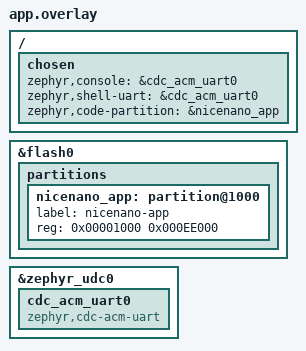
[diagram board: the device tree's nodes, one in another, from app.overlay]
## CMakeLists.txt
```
cmake_minimum_required(VERSION 3.20.0)
find_package(Zephyr REQUIRED HINTS $ENV{ZEPHYR_BASE})
project(nrf52840_nicenano_wire_check)
target_sources(app PRIVATE src/main.c ../nrf52840_nicenano_common/ael_usb.c)
```

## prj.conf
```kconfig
CONFIG_GPIO=y
CONFIG_SERIAL=y
CONFIG_CONSOLE=y
CONFIG_UART_CONSOLE=y
CONFIG_STDOUT_CONSOLE=y
CONFIG_PRINTK=y
CONFIG_USB_DEVICE_STACK_NEXT=y
CONFIG_USBD_CDC_ACM_CLASS=y
CONFIG_UART_LINE_CTRL=y
CONFIG_HWINFO=y
CONFIG_BUILD_OUTPUT_UF2=y
CONFIG_BUILD_OUTPUT_UF2_FAMILY_ID="0x239A00B3"
CONFIG_FLASH_LOAD_OFFSET=0x1000
CONFIG_FLASH_LOAD_SIZE=0xEE000
```

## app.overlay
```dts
/ {
    chosen {
        zephyr,console = &cdc_acm_uart0;
        zephyr,shell-uart = &cdc_acm_uart0;
        zephyr,code-partition = &nicenano_app;
    };
};

&flash0 {
    partitions {
        nicenano_app: partition@1000 {
            label = "nicenano-app";
            reg = <0x00001000 0x000EE000>;
        };
    };
};

&zephyr_udc0 {
    cdc_acm_uart0: cdc_acm_uart0 {
        compatible = "zephyr,cdc-acm-uart";
    };
};
```

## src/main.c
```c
/*
 * AEL Pre-Stage-2 — nRF52840 nice!nano wire connectivity check
 *
 * Drives each output pin LOW then HIGH and reads the paired input pin.
 * Reports CONNECTED if input follows output, OPEN otherwise.
 *
 * Connections tested:
 *   P0.17 (OUT) ↔ P0.20 (IN)   — GPIO/UART loopback wire
 *   P0.22 (OUT) → P0.24 (IN)   — PWM capture wire
 *   P1.10 (OUT) → P1.13 (IN)   — SPI MOSI→MISO wire
 *
 * Reports:
 *   [WIRE] P0.17->P0.20 CONNECTED|OPEN
 *   [WIRE] P0.22->P0.24 CONNECTED|OPEN
 *   [WIRE] P1.10->P1.13 CONNECTED|OPEN
 *   AEL_WIRE_CHECK_PASS|FAIL
 */

#include <zephyr/kernel.h>
#include <zephyr/sys/printk.h>
#include <zephyr/drivers/gpio.h>
#include "../../nrf52840_nicenano_common/ael_usb.h"

static const struct device *gpio0;
static const struct device *gpio1;

static bool check_wire(const char *tag,
                        const struct device *out_dev, int out_pin,
                        const struct device *in_dev,  int in_pin)
{
    gpio_pin_configure(out_dev, out_pin, GPIO_OUTPUT_INACTIVE);
    gpio_pin_configure(in_dev,  in_pin,  GPIO_INPUT);

    /* Drive LOW, read */
    gpio_pin_set(out_dev, out_pin, 0);
    k_busy_wait(50);
    int r0 = gpio_pin_get(in_dev, in_pin);

    /* Drive HIGH, read */
    gpio_pin_set(out_dev, out_pin, 1);
    k_busy_wait(50);
    int r1 = gpio_pin_get(in_dev, in_pin);

    /* Tristate output, check if input floats (connected → stays at last driven value) */
    gpio_pin_configure(out_dev, out_pin, GPIO_INPUT);

    bool connected = (r0 == 0 && r1 == 1);
    printk("[WIRE] %s %s\n", tag, connected ? "CONNECTED" : "OPEN");
    return connected;
}

int main(void)
{
    ael_usb_init();
    k_msleep(1500);

    gpio0 = DEVICE_DT_GET(DT_NODELABEL(gpio0));
    gpio1 = DEVICE_DT_GET(DT_NODELABEL(gpio1));

    if (!device_is_ready(gpio0) || !device_is_ready(gpio1)) {
        printk("[WIRE] gpio_not_ready FAIL\n");
        printk("AEL_WIRE_CHECK_FAIL\n");
        while (1) {
            if (atomic_get(&ael_bl_flag)) { k_msleep(50); ael_enter_bootloader(); }
            k_msleep(3000);
        }
    }

    printk("AEL_WIRE_CHECK_START\n");

    bool all_ok = true;
    all_ok &= check_wire("P0.17->P0.20", gpio0, 17, gpio0, 20);
    all_ok &= check_wire("P0.22->P0.24", gpio0, 22, gpio0, 24);
    all_ok &= check_wire("P1.10->P1.13", gpio1, 10, gpio1, 13);

    while (1) {
        if (atomic_get(&ael_bl_flag)) { k_msleep(50); ael_enter_bootloader(); }
        printk("AEL_WIRE_CHECK_%s\n", all_ok ? "PASS" : "FAIL");
        k_msleep(3000);
    }
    return 0;
}
```
